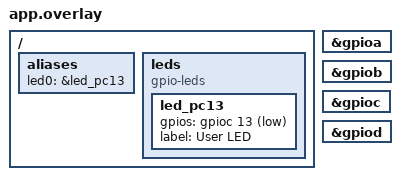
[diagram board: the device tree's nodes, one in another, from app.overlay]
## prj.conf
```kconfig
CONFIG_GPIO=y
CONFIG_LOG=y
CONFIG_LOG_MODE_IMMEDIATE=y
```

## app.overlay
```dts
/ {
	aliases {
		led0 = &led_pc13;
	};

	leds {
		compatible = "gpio-leds";
		led_pc13: led_pc13 {
			gpios = <&gpioc 13 GPIO_ACTIVE_LOW>;
			label = "User LED";
		};
	};
};

&gpioa { status = "okay"; };
&gpiob { status = "okay"; };
&gpioc { status = "okay"; };
&gpiod { status = "okay"; };
```

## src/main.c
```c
/*
 * Copyright (c) 2016 Intel Corporation
 *
 * SPDX-License-Identifier: Apache-2.0
 */

#include <zephyr/kernel.h>
#include <zephyr/drivers/gpio.h>
#include <zephyr/logging/log.h>

LOG_MODULE_REGISTER(blinky, LOG_LEVEL_INF);

/* The devicetree node identifier for the "led0" alias. */
#define LED0_NODE DT_ALIAS(led0)

/*
 * A build error on this line means your board is unsupported.
 * See the sample documentation for information on how to fix this.
 */
static const struct gpio_dt_spec led = GPIO_DT_SPEC_GET(LED0_NODE, gpios);

int main(void)
{
	int ret;

    LOG_INF("Starting Blinky on %s pin %d", led.port->name, led.pin);

	if (!gpio_is_ready_dt(&led)) {
        LOG_ERR("Error: GPIO device is not ready");
		return 0;
	}

	ret = gpio_pin_configure_dt(&led, GPIO_OUTPUT_ACTIVE);
	if (ret < 0) {
        LOG_ERR("Error: Failed to configure GPIO");
		return 0;
	}

	while (1) {
		ret = gpio_pin_toggle_dt(&led);
		if (ret < 0) {
            LOG_ERR("Error: Failed to toggle GPIO");
			return 0;
		}
        LOG_INF("Blink! LED State Toggled.");
		k_msleep(1000);
	}
	return 0;
}
```
